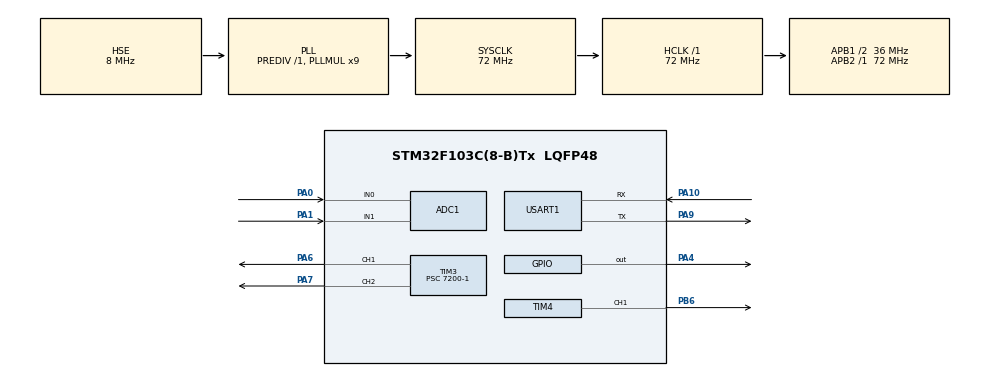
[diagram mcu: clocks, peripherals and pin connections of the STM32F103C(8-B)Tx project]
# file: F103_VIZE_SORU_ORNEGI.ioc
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ADC1.Channel-0\#ChannelRegularConversion=ADC_CHANNEL_0
ADC1.Channel-1\#ChannelRegularConversion=ADC_CHANNEL_1
ADC1.ContinuousConvMode=ENABLE
ADC1.NbrOfConversion=2
ADC1.NbrOfConversionFlag=1
ADC1.Rank-0\#ChannelRegularConversion=1
ADC1.Rank-1\#ChannelRegularConversion=2
ADC1.SamplingTime-0\#ChannelRegularConversion=ADC_SAMPLETIME_28CYCLES_5
ADC1.SamplingTime-1\#ChannelRegularConversion=ADC_SAMPLETIME_28CYCLES_5
ADC1.master=1
Dma.ADC1.0.Direction=DMA_PERIPH_TO_MEMORY
Dma.ADC1.0.Instance=DMA1_Channel1
Dma.ADC1.0.MemDataAlignment=DMA_MDATAALIGN_WORD
Dma.ADC1.0.MemInc=DMA_MINC_ENABLE
Dma.ADC1.0.Mode=DMA_CIRCULAR
Dma.ADC1.0.PeriphDataAlignment=DMA_PDATAALIGN_WORD
Dma.ADC1.0.PeriphInc=DMA_PINC_DISABLE
Dma.ADC1.0.Priority=DMA_PRIORITY_LOW
Dma.Request0=ADC1
Dma.Request1=USART1_RX
Dma.USART1_RX.1.Direction=DMA_PERIPH_TO_MEMORY
Dma.USART1_RX.1.Instance=DMA1_Channel5
Dma.USART1_RX.1.MemDataAlignment=DMA_MDATAALIGN_BYTE
Dma.USART1_RX.1.MemInc=DMA_MINC_ENABLE
Dma.USART1_RX.1.Mode=DMA_NORMAL
Dma.USART1_RX.1.PeriphDataAlignment=DMA_PDATAALIGN_BYTE
Dma.USART1_RX.1.PeriphInc=DMA_PINC_DISABLE
Dma.USART1_RX.1.Priority=DMA_PRIORITY_LOW
Mcu.Family=STM32F1
Mcu.Name=STM32F103C(8-B)Tx
Mcu.Package=LQFP48
NVIC.ADC1_2_IRQn=true\:0\:0\:false\:false\:true\:true\:true
NVIC.DMA1_Channel1_IRQn=true\:0\:0\:false\:false\:true\:false\:true
NVIC.DMA1_Channel5_IRQn=true\:0\:0\:false\:false\:true\:false\:true
NVIC.PriorityGroup=NVIC_PRIORITYGROUP_4
NVIC.TIM4_IRQn=true\:0\:0\:false\:false\:true\:true\:true
NVIC.USART1_IRQn=true\:0\:0\:false\:false\:true\:true\:true
PA0-WKUP.Signal=ADCx_IN0
PA1.Signal=ADCx_IN1
PA10.Mode=Asynchronous
PA10.Signal=USART1_RX
PA13.Mode=Serial_Wire
PA13.Signal=SYS_JTMS-SWDIO
PA14.Mode=Serial_Wire
PA14.Signal=SYS_JTCK-SWCLK
PA4.Signal=GPIO_Output
PA6.Signal=S_TIM3_CH1
PA7.Signal=S_TIM3_CH2
PA9.Mode=Asynchronous
PA9.Signal=USART1_TX
PB6.Signal=S_TIM4_CH1
PD0-OSC_IN.Mode=HSE-External-Oscillator
PD0-OSC_IN.Signal=RCC_OSC_IN
PD1-OSC_OUT.Mode=HSE-External-Oscillator
PD1-OSC_OUT.Signal=RCC_OSC_OUT
ProjectManager.HeapSize=0x200
ProjectManager.StackSize=0x400
ProjectManager.TargetToolchain=SW4STM32
RCC.ADCPresc=RCC_ADCPCLK2_DIV6
RCC.AHBFreq_Value=72000000
RCC.APB1CLKDivider=RCC_HCLK_DIV2
RCC.APB1Freq_Value=36000000
RCC.APB1TimFreq_Value=72000000
RCC.APB2Freq_Value=72000000
RCC.APB2TimFreq_Value=72000000
RCC.HCLKFreq_Value=72000000
RCC.PLLMUL=RCC_PLL_MUL9
RCC.PLLSourceVirtual=RCC_PLLSOURCE_HSE
RCC.SYSCLKFreq_VALUE=72000000
RCC.SYSCLKSource=RCC_SYSCLKSOURCE_PLLCLK
RCC.USBFreq_Value=72000000
SH.ADCx_IN0.0=ADC1_IN0,IN0
SH.ADCx_IN1.0=ADC1_IN1,IN1
SH.S_TIM3_CH1.0=TIM3_CH1,PWM Generation1 CH1
SH.S_TIM3_CH2.0=TIM3_CH2,PWM Generation2 CH2
SH.S_TIM4_CH1.0=TIM4_CH1,PWM Generation1 CH1
TIM3.Channel-PWM\ Generation1\ CH1=TIM_CHANNEL_1
TIM3.Channel-PWM\ Generation2\ CH2=TIM_CHANNEL_2
TIM3.OCFastMode_PWM-PWM\ Generation1\ CH1=TIM_OCFAST_ENABLE
TIM3.OCFastMode_PWM-PWM\ Generation2\ CH2=TIM_OCFAST_ENABLE
TIM3.Period=1000-1
TIM3.Prescaler=7200-1
TIM4.Channel-PWM\ Generation1\ CH1=TIM_CHANNEL_1
TIM4.Period=3600-1
TIM4.Prescaler=400-1
USART1.VirtualMode=VM_ASYNC
board=custom

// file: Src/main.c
/* USER CODE BEGIN Header */
/**
  ******************************************************************************
  * @file           : main.c
  * @brief          : Main program body
  ******************************************************************************
  * @attention
  *
  * <h2><center>&copy; Copyright (c) 2019 STMicroelectronics.
  * All rights reserved.</center></h2>
  *
  * This software component is licensed by ST under BSD 3-Clause license,
  * the "License"; You may not use this file except in compliance with the
  * License. You may obtain a copy of the License at:
  *                        opensource.org/licenses/BSD-3-Clause
  *
  ******************************************************************************
  */
/* USER CODE END Header */

#include "main.h"

ADC_HandleTypeDef hadc1;
DMA_HandleTypeDef hdma_adc1;

TIM_HandleTypeDef htim3;
TIM_HandleTypeDef htim4;

UART_HandleTypeDef huart1;
DMA_HandleTypeDef hdma_usart1_rx;

/* USER CODE BEGIN PV */

uint8_t rxBuffer[1];
uint8_t txBuffer[20]="UART BASLADI";
uint32_t ADC_DMA_Value[2];

/* USER CODE END PV */

void SystemClock_Config(void);
static void MX_GPIO_Init(void);
static void MX_DMA_Init(void);
static void MX_ADC1_Init(void);
static void MX_TIM3_Init(void);
static void MX_TIM4_Init(void);
static void MX_USART1_UART_Init(void);

int main(void)
{

  /* MCU Configuration--------------------------------------------------------*/

  /* Reset of all peripherals, Initializes the Flash interface and the Systick. */
  HAL_Init();

  /* Configure the system clock */
  SystemClock_Config();

  /* Initialize all configured peripherals */
  MX_GPIO_Init();
  MX_DMA_Init();
  MX_ADC1_Init();
  MX_TIM3_Init();
  MX_TIM4_Init();
  MX_USART1_UART_Init();

  /* Infinite loop */
  /* USER CODE BEGIN WHILE */
	if (HAL_UART_Transmit(&huart1, (uint8_t*)txBuffer, sizeof(txBuffer),100) != HAL_OK)
	{
		Error_Handler();
	}

	/*## STEP 2:  ADC BAÞLAT */
	if (HAL_ADC_Start_DMA(&hadc1, (uint32_t*)ADC_DMA_Value, 2)!= HAL_OK)
	{
		Error_Handler();
	}

	if (HAL_UART_Receive_DMA(&huart1, (uint8_t*)rxBuffer, 1) != HAL_OK)
	{
		Error_Handler();
	}
  while (1);
  /* USER CODE END 3 */
}

 void HAL_ADC_ConvCpltCallback(ADC_HandleTypeDef* hadc)
{
	 __HAL_TIM_SET_COMPARE(&htim3, TIM_CHANNEL_1, ADC_DMA_Value[1]/4);
	 __HAL_TIM_SET_COMPARE(&htim3, TIM_CHANNEL_2, ADC_DMA_Value[1]/4);
}

 void HAL_UART_RxCpltCallback(UART_HandleTypeDef *huart)
{
	 if(rxBuffer[0]=='e')
	 {
		HAL_GPIO_WritePin(GPIOA,GPIO_PIN_4,GPIO_PIN_SET);
		HAL_TIM_PWM_Stop(&htim3, TIM_CHANNEL_2);
		HAL_TIM_PWM_Start(&htim3, TIM_CHANNEL_1);
		__HAL_TIM_SET_COMPARE(&htim3, TIM_CHANNEL_1, ADC_DMA_Value[1]/4);
	 }
	 else if(rxBuffer[0]=='d')
	 {
		HAL_GPIO_WritePin(GPIOA,GPIO_PIN_4,GPIO_PIN_SET);
		HAL_TIM_PWM_Stop(&htim3, TIM_CHANNEL_1);
		HAL_TIM_PWM_Start(&htim3, TIM_CHANNEL_2);
		__HAL_TIM_SET_COMPARE(&htim3, TIM_CHANNEL_2, ADC_DMA_Value[1]/4);
	 }
	 else if(rxBuffer[0]=='c')
	 {

		HAL_TIM_PWM_Stop(&htim3, TIM_CHANNEL_1);
		HAL_TIM_PWM_Stop(&htim3, TIM_CHANNEL_2);

	 }
	 if(rxBuffer[0]=='f')
	 {
		HAL_TIM_PWM_Start(&htim4, TIM_CHANNEL_1);
		__HAL_TIM_SET_COMPARE(&htim4, TIM_CHANNEL_1, 110);
	 }
	 else if(rxBuffer[0]=='s')
	 {
		HAL_TIM_PWM_Start(&htim4, TIM_CHANNEL_1);
		__HAL_TIM_SET_COMPARE(&htim4, TIM_CHANNEL_1, 250);
	 }
	 else
	 {
			HAL_TIM_PWM_Start(&htim4, TIM_CHANNEL_1);
			__HAL_TIM_SET_COMPARE(&htim4, TIM_CHANNEL_1, 180);
		 }

	 if (HAL_UART_Receive_DMA(&huart1, (uint8_t*)rxBuffer, 1) != HAL_OK)
		{
			Error_Handler();
		}
}
void SystemClock_Config(void)
{
  RCC_OscInitTypeDef RCC_OscInitStruct = {0};
  RCC_ClkInitTypeDef RCC_ClkInitStruct = {0};
  RCC_PeriphCLKInitTypeDef PeriphClkInit = {0};

  /** Initializes the CPU, AHB and APB busses clocks
  */
  RCC_OscInitStruct.OscillatorType = RCC_OSCILLATORTYPE_HSE;
  RCC_OscInitStruct.HSEState = RCC_HSE_ON;
  RCC_OscInitStruct.HSEPredivValue = RCC_HSE_PREDIV_DIV1;
  RCC_OscInitStruct.HSIState = RCC_HSI_ON;
  RCC_OscInitStruct.PLL.PLLState = RCC_PLL_ON;
  RCC_OscInitStruct.PLL.PLLSource = RCC_PLLSOURCE_HSE;
  RCC_OscInitStruct.PLL.PLLMUL = RCC_PLL_MUL9;
  if (HAL_RCC_OscConfig(&RCC_OscInitStruct) != HAL_OK)
  {
    Error_Handler();
  }
  /** Initializes the CPU, AHB and APB busses clocks
  */
  RCC_ClkInitStruct.ClockType = RCC_CLOCKTYPE_HCLK|RCC_CLOCKTYPE_SYSCLK
                              |RCC_CLOCKTYPE_PCLK1|RCC_CLOCKTYPE_PCLK2;
  RCC_ClkInitStruct.SYSCLKSource = RCC_SYSCLKSOURCE_PLLCLK;
  RCC_ClkInitStruct.AHBCLKDivider = RCC_SYSCLK_DIV1;
  RCC_ClkInitStruct.APB1CLKDivider = RCC_HCLK_DIV2;
  RCC_ClkInitStruct.APB2CLKDivider = RCC_HCLK_DIV1;

  if (HAL_RCC_ClockConfig(&RCC_ClkInitStruct, FLASH_LATENCY_2) != HAL_OK)
  {
    Error_Handler();
  }
  PeriphClkInit.PeriphClockSelection = RCC_PERIPHCLK_ADC;
  PeriphClkInit.AdcClockSelection = RCC_ADCPCLK2_DIV6;
  if (HAL_RCCEx_PeriphCLKConfig(&PeriphClkInit) != HAL_OK)
  {
    Error_Handler();
  }
}

static void MX_ADC1_Init(void)
{

  ADC_ChannelConfTypeDef sConfig = {0};

  /** Common config
  */
  hadc1.Instance = ADC1;
  hadc1.Init.ScanConvMode = ADC_SCAN_ENABLE;
  hadc1.Init.ContinuousConvMode = ENABLE;
  hadc1.Init.DiscontinuousConvMode = DISABLE;
  hadc1.Init.ExternalTrigConv = ADC_SOFTWARE_START;
  hadc1.Init.DataAlign = ADC_DATAALIGN_RIGHT;
  hadc1.Init.NbrOfConversion = 2;
  if (HAL_ADC_Init(&hadc1) != HAL_OK)
  {
    Error_Handler();
  }
  /** Configure Regular Channel
  */
  sConfig.Channel = ADC_CHANNEL_0;
  sConfig.Rank = ADC_REGULAR_RANK_1;
  sConfig.SamplingTime = ADC_SAMPLETIME_28CYCLES_5;
  if (HAL_ADC_ConfigChannel(&hadc1, &sConfig) != HAL_OK)
  {
    Error_Handler();
  }
  /** Configure Regular Channel
  */
  sConfig.Channel = ADC_CHANNEL_1;
  sConfig.Rank = ADC_REGULAR_RANK_2;
  if (HAL_ADC_ConfigChannel(&hadc1, &sConfig) != HAL_OK)
  {
    Error_Handler();
  }

}

static void MX_TIM3_Init(void)
{

  TIM_MasterConfigTypeDef sMasterConfig = {0};
  TIM_OC_InitTypeDef sConfigOC = {0};

  htim3.Instance = TIM3;
  htim3.Init.Prescaler = 72-1;
  htim3.Init.CounterMode = TIM_COUNTERMODE_UP;
  htim3.Init.Period = 1000-1;
  htim3.Init.ClockDivision = TIM_CLOCKDIVISION_DIV1;
  htim3.Init.AutoReloadPreload = TIM_AUTORELOAD_PRELOAD_DISABLE;
  if (HAL_TIM_PWM_Init(&htim3) != HAL_OK)
  {
    Error_Handler();
  }
  sMasterConfig.MasterOutputTrigger = TIM_TRGO_RESET;
  sMasterConfig.MasterSlaveMode = TIM_MASTERSLAVEMODE_DISABLE;
  if (HAL_TIMEx_MasterConfigSynchronization(&htim3, &sMasterConfig) != HAL_OK)
  {
    Error_Handler();
  }
  sConfigOC.OCMode = TIM_OCMODE_PWM1;
  sConfigOC.Pulse = 0;
  sConfigOC.OCPolarity = TIM_OCPOLARITY_HIGH;
  sConfigOC.OCFastMode = TIM_OCFAST_ENABLE;
  if (HAL_TIM_PWM_ConfigChannel(&htim3, &sConfigOC, TIM_CHANNEL_1) != HAL_OK)
  {
    Error_Handler();
  }
  if (HAL_TIM_PWM_ConfigChannel(&htim3, &sConfigOC, TIM_CHANNEL_2) != HAL_OK)
  {
    Error_Handler();
  }
  HAL_TIM_MspPostInit(&htim3);

}

static void MX_TIM4_Init(void)
{

  TIM_MasterConfigTypeDef sMasterConfig = {0};
  TIM_OC_InitTypeDef sConfigOC = {0};

  htim4.Instance = TIM4;
  htim4.Init.Prescaler = 400-1;
  htim4.Init.CounterMode = TIM_COUNTERMODE_UP;
  htim4.Init.Period = 3600-1;
  htim4.Init.ClockDivision = TIM_CLOCKDIVISION_DIV1;
  htim4.Init.AutoReloadPreload = TIM_AUTORELOAD_PRELOAD_DISABLE;
  if (HAL_TIM_PWM_Init(&htim4) != HAL_OK)
  {
    Error_Handler();
  }
  sMasterConfig.MasterOutputTrigger = TIM_TRGO_RESET;
  sMasterConfig.MasterSlaveMode = TIM_MASTERSLAVEMODE_DISABLE;
  if (HAL_TIMEx_MasterConfigSynchronization(&htim4, &sMasterConfig) != HAL_OK)
  {
    Error_Handler();
  }
  sConfigOC.OCMode = TIM_OCMODE_PWM1;
  sConfigOC.Pulse = 0;
  sConfigOC.OCPolarity = TIM_OCPOLARITY_HIGH;
  sConfigOC.OCFastMode = TIM_OCFAST_DISABLE;
  if (HAL_TIM_PWM_ConfigChannel(&htim4, &sConfigOC, TIM_CHANNEL_1) != HAL_OK)
  {
    Error_Handler();
  }
  HAL_TIM_MspPostInit(&htim4);

}

static void MX_USART1_UART_Init(void)
{

  huart1.Instance = USART1;
  huart1.Init.BaudRate = 115200;
  huart1.Init.WordLength = UART_WORDLENGTH_8B;
  huart1.Init.StopBits = UART_STOPBITS_1;
  huart1.Init.Parity = UART_PARITY_NONE;
  huart1.Init.Mode = UART_MODE_TX_RX;
  huart1.Init.HwFlowCtl = UART_HWCONTROL_NONE;
  huart1.Init.OverSampling = UART_OVERSAMPLING_16;
  if (HAL_UART_Init(&huart1) != HAL_OK)
  {
    Error_Handler();
  }

}

static void MX_DMA_Init(void)
{
  /* DMA controller clock enable */
  __HAL_RCC_DMA1_CLK_ENABLE();

  /* DMA interrupt init */
  /* DMA1_Channel1_IRQn interrupt configuration */
  HAL_NVIC_SetPriority(DMA1_Channel1_IRQn, 0, 0);
  HAL_NVIC_EnableIRQ(DMA1_Channel1_IRQn);
  /* DMA1_Channel5_IRQn interrupt configuration */
  HAL_NVIC_SetPriority(DMA1_Channel5_IRQn, 0, 0);
  HAL_NVIC_EnableIRQ(DMA1_Channel5_IRQn);

}

static void MX_GPIO_Init(void)
{
  GPIO_InitTypeDef GPIO_InitStruct = {0};

  /* GPIO Ports Clock Enable */
  __HAL_RCC_GPIOD_CLK_ENABLE();
  __HAL_RCC_GPIOA_CLK_ENABLE();
  __HAL_RCC_GPIOB_CLK_ENABLE();

  /*Configure GPIO pin Output Level */
  HAL_GPIO_WritePin(GPIOA, GPIO_PIN_4, GPIO_PIN_RESET);

  /*Configure GPIO pin : PA4 */
  GPIO_InitStruct.Pin = GPIO_PIN_4;
  GPIO_InitStruct.Mode = GPIO_MODE_OUTPUT_PP;
  GPIO_InitStruct.Pull = GPIO_NOPULL;
  GPIO_InitStruct.Speed = GPIO_SPEED_FREQ_LOW;
  HAL_GPIO_Init(GPIOA, &GPIO_InitStruct);

}

void Error_Handler(void)
{
}

/************************ (C) COPYRIGHT STMicroelectronics *****END OF FILE****/
